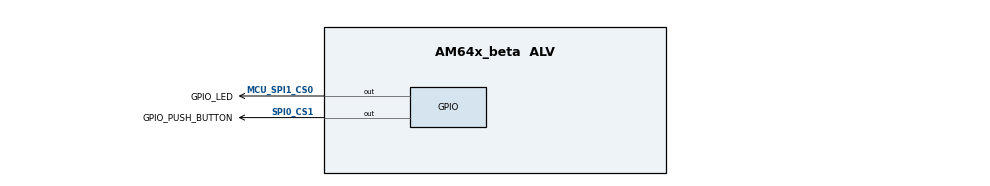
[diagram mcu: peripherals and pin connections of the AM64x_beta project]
/**
 * @cliArgs --device "AM64x_beta" --package "ALV" --part "Default" --context "r5fss0-0" --product "MCU_PLUS_SDK@07.03.00"
 * @versions {"data":"2021012919","timestamp":"2021012919","tool":"1.8.0+1785","templates":null}
 */

/**
 * Import the modules used in this configuration.
 */
const gpio       = scripting.addModule("/drivers/gpio/gpio", {}, false);
const gpio1      = gpio.addInstance();
const gpio2      = gpio.addInstance();
const debug_log  = scripting.addModule("/kernel/dpl/debug_log");
const mpu_armv7  = scripting.addModule("/kernel/dpl/mpu_armv7", {}, false);
const mpu_armv71 = mpu_armv7.addInstance();
const mpu_armv72 = mpu_armv7.addInstance();
const mpu_armv73 = mpu_armv7.addInstance();
const mpu_armv74 = mpu_armv7.addInstance();
const timer           = scripting.addModule("/kernel/dpl/timer", {}, false);
const timer1          = timer.addInstance();

/**
 * Write custom configuration values to the imported modules.
 */
gpio1.useMcuDomainPeripherals  = true;
gpio1.$name                    = "GPIO_LED";
gpio1.pinDir                   = "OUTPUT";
gpio1.MCU_GPIO.$assign         = "MCU_GPIO0";
gpio1.MCU_GPIO.gpioPin.$assign = "MCU_SPI1_CS0";

gpio2.$name                = "GPIO_PUSH_BUTTON";
gpio2.GPIO.$assign         = "GPIO1";
gpio2.GPIO.gpioPin.$assign = "SPI0_CS1";

debug_log.enableUartLog            = true;
debug_log.uartLog.$name            = "CONFIG_UART_CONSOLE";
debug_log.uartLog.UART.$assign     = "USART0";
debug_log.uartLog.UART.RXD.$assign = "UART0_RXD";
debug_log.uartLog.UART.TXD.$assign = "UART0_TXD";

mpu_armv71.$name             = "CONFIG_MPU_REGION0";
mpu_armv71.size              = 31;
mpu_armv71.attributes        = "Device";
mpu_armv71.accessPermissions = "Supervisor RD+WR, User RD";
mpu_armv71.allowExecute      = false;

mpu_armv72.$name             = "CONFIG_MPU_REGION1";
mpu_armv72.size              = 15;
mpu_armv72.accessPermissions = "Supervisor RD+WR, User RD";

mpu_armv73.$name             = "CONFIG_MPU_REGION2";
mpu_armv73.baseAddr          = 0x41010000;
mpu_armv73.size              = 15;
mpu_armv73.accessPermissions = "Supervisor RD+WR, User RD";

mpu_armv74.$name             = "CONFIG_MPU_REGION3";
mpu_armv74.baseAddr          = 0x70000000;
mpu_armv74.size              = 21;
mpu_armv74.accessPermissions = "Supervisor RD+WR, User RD";

timer1.$name             = "CONFIG_TIMER_ESM_TEST_Pin";
timer1.enableOneShotMode = true;
//timer1.timerCallback     = "timerExpPinDisable";
timer1.usecPerTick       = 10000;
